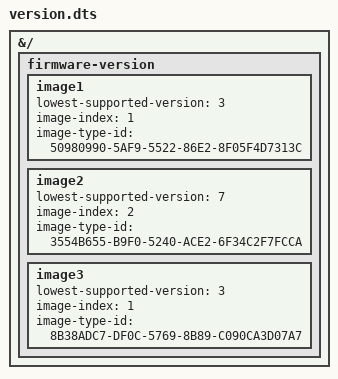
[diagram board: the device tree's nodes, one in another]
// SPDX-License-Identifier: GPL-2.0+

/dts-v1/;
/plugin/;

&{/} {
	firmware-version {
		image1 {
			lowest-supported-version = <3>;
			image-index = <1>;
			image-type-id = "50980990-5AF9-5522-86E2-8F05F4D7313C";
		};
		image2 {
			lowest-supported-version = <7>;
			image-index = <2>;
			image-type-id = "3554B655-B9F0-5240-ACE2-6F34C2F7FCCA";
		};
		image3 {
			lowest-supported-version = <3>;
			image-index = <1>;
			image-type-id = "8B38ADC7-DF0C-5769-8B89-C090CA3D07A7";
		};
	};
};
